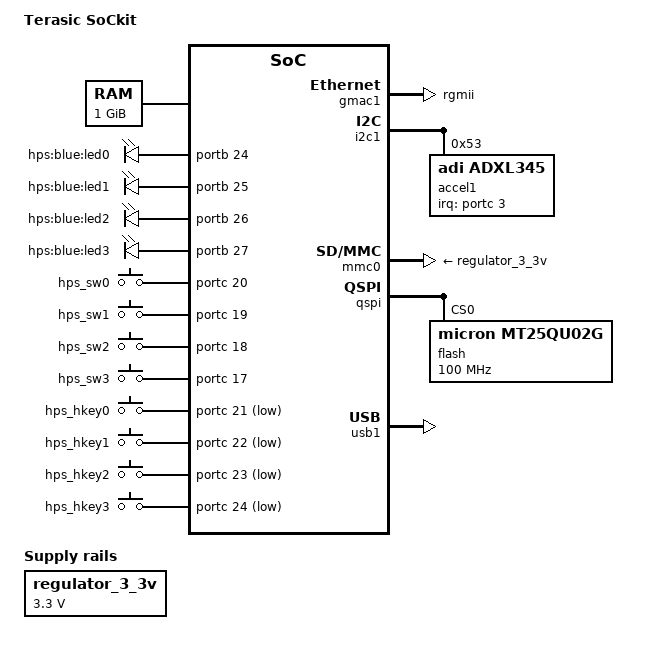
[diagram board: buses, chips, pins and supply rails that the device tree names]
#include "socfpga_cyclone5.dtsi"
/ {
	model = "Terasic SoCkit";
	compatible = "terasic,socfpga-cyclone5-sockit", "altr,socfpga-cyclone5", "altr,socfpga";
	chosen {
		bootargs = "earlyprintk";
		stdout-path = "serial0:115200n8";
	};
	memory@0 {
		name = "memory";
		device_type = "memory";
		reg = <0x0 0x40000000>;  
	};
	aliases {
		ethernet0 = &gmac1;
	};
	leds {
		compatible = "gpio-leds";
		hps_led0 {
			label = "hps:blue:led0";
			gpios = <&portb 24 0>;	 
			linux,default-trigger = "heartbeat";
		};
		hps_led1 {
			label = "hps:blue:led1";
			gpios = <&portb 25 0>;	 
			linux,default-trigger = "heartbeat";
		};
		hps_led2 {
			label = "hps:blue:led2";
			gpios = <&portb 26 0>;	 
			linux,default-trigger = "heartbeat";
		};
		hps_led3 {
			label = "hps:blue:led3";
			gpios = <&portb 27 0>;	 
			linux,default-trigger = "heartbeat";
		};
	};
	gpio-keys {
		compatible = "gpio-keys";
		hps_sw0 {
			label = "hps_sw0";
			gpios = <&portc 20 0>;	 
			linux,input-type = <5>;	 
			linux,code = <0x0>;	 
		};
		hps_sw1 {
			label = "hps_sw1";
			gpios = <&portc 19 0>;	 
			linux,input-type = <5>;	 
			linux,code = <0x5>;	 
		};
		hps_sw2 {
			label = "hps_sw2";
			gpios = <&portc 18 0>;	 
			linux,input-type = <5>;	 
			linux,code = <0xa>;	 
		};
		hps_sw3 {
			label = "hps_sw3";
			gpios = <&portc 17 0>;	 
			linux,input-type = <5>;	 
			linux,code = <0xc>;	 
		};
		hps_hkey0 {
			label = "hps_hkey0";
			gpios = <&portc 21 1>;	 
			linux,code = <187>;	 
		};
		hps_hkey1 {
			label = "hps_hkey1";
			gpios = <&portc 22 1>;	 
			linux,code = <188>;	 
		};
		hps_hkey2 {
			label = "hps_hkey2";
			gpios = <&portc 23 1>;	 
			linux,code = <189>;	 
		};
		hps_hkey3 {
			label = "hps_hkey3";
			gpios = <&portc 24 1>;	 
			linux,code = <190>;	 
		};
	};
	regulator_3_3v: regulator {
		compatible = "regulator-fixed";
		regulator-name = "VCC3P3";
		regulator-min-microvolt = <3300000>;
		regulator-max-microvolt = <3300000>;
	};
};
&gmac1 {
	status = "okay";
	phy-mode = "rgmii";
	rxd0-skew-ps = <0>;
	rxd1-skew-ps = <0>;
	rxd2-skew-ps = <0>;
	rxd3-skew-ps = <0>;
	txen-skew-ps = <0>;
	txc-skew-ps = <2600>;
	rxdv-skew-ps = <0>;
	rxc-skew-ps = <2000>;
};
&gpio0 {	 
	status = "okay";
};
&gpio1 {	 
	status = "okay";
};
&gpio2 {	 
	status = "okay";
};
&i2c1 {
	status = "okay";
	accel1: accelerometer@53 {
		compatible = "adi,adxl345";
		reg = <0x53>;
		interrupt-parent = <&portc>;
		interrupts = <3 2>;
	};
};
&mmc0 {
	vmmc-supply = <&regulator_3_3v>;
	vqmmc-supply = <&regulator_3_3v>;
	status = "okay";
};
&qspi {
	status = "okay";
	flash: flash@0 {
		#address-cells = <1>;
		#size-cells = <1>;
		compatible = "micron,mt25qu02g", "jedec,spi-nor";
		reg = <0>;
		spi-max-frequency = <100000000>;
		m25p,fast-read;
		cdns,page-size = <256>;
		cdns,block-size = <16>;
		cdns,read-delay = <4>;
		cdns,tshsl-ns = <50>;
		cdns,tsd2d-ns = <50>;
		cdns,tchsh-ns = <4>;
		cdns,tslch-ns = <4>;
	};
};
&usb1 {
	status = "okay";
};
